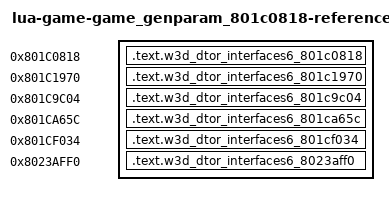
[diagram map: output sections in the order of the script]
/* Generated reference-only placements. All bodies are source-built. */
OUTPUT_FORMAT("elf32-powerpc")
OUTPUT_ARCH(powerpc)
ENTRY(w3d_dtor_interfaces6_801c0818)
_SDA_BASE_ = 0x804b2540;
_SDA2_BASE_ = 0x804c2540;
fn_801b5bd4 = 0x801b5bd4;
fn_801c9134 = 0x801c9134;
fn_801ce064 = 0x801ce064;
fn_801ea138 = 0x801ea138;
fn_801ea740 = 0x801ea740;
w3d_vtable_80414da8 = 0x80414da8;
w3d_vtable_80414e48 = 0x80414e48;
w3d_vtable_80415d80 = 0x80415d80;
w3d_vtable_804162a8 = 0x804162a8;
w3d_vtable_80416320 = 0x80416320;
w3d_vtable_8041ae00 = 0x8041ae00;
SECTIONS {
  .text.w3d_dtor_interfaces6_801c0818 0x801c0818 : { *(.text.w3d_dtor_interfaces6_801c0818) }
  .text.w3d_dtor_interfaces6_801c1970 0x801c1970 : { *(.text.w3d_dtor_interfaces6_801c1970) }
  .text.w3d_dtor_interfaces6_801c9c04 0x801c9c04 : { *(.text.w3d_dtor_interfaces6_801c9c04) }
  .text.w3d_dtor_interfaces6_801ca65c 0x801ca65c : { *(.text.w3d_dtor_interfaces6_801ca65c) }
  .text.w3d_dtor_interfaces6_801cf034 0x801cf034 : { *(.text.w3d_dtor_interfaces6_801cf034) }
  .text.w3d_dtor_interfaces6_8023aff0 0x8023aff0 : { *(.text.w3d_dtor_interfaces6_8023aff0) }
  /DISCARD/ : { *(.text*) *(.rodata*) *(.data*) *(.bss*) *(.sdata*) *(.sbss*) *(.comment) }
}
